AUTOSAR XML (schema 00044)
package /E40_Platform_System_SystemPackage/Components
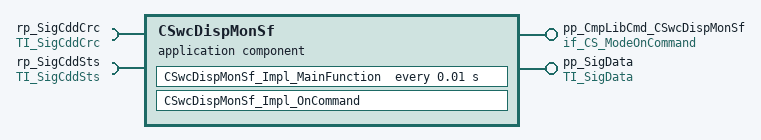
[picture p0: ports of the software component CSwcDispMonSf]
  application sw component type CSwcDispMonSf
    provide port pp_CmpLibCmd_CSwcDispMonSf: server-com-spec{operation=Impl_OnCommand, queue-length=1}, provided-interface=if_CS_ModeOnCommand
    provide port pp_SigData: nonqueued-sender-com-spec{data-element=sig0_port, init-value=constant-reference=CSwcDispMonSfsig0_portValue0}, provided-interface=TI_SigData
    require port rp_SigCddCrc: client-com-spec=Impl_sig_get_win_crc_data, required-interface=TI_SigCddCrc
    require port rp_SigCddSts: nonqueued-receiver-com-spec{data-element=win_violation_output, init-value=constant-reference=CSwcDispMonSfwin_violation_outputValue0}, required-interface=TI_SigCddSts
    behavior IB_CSwcDispMonSf
      timing event TECSwcDispMonSf_Impl_MainFunction: start-on-event=CSwcDispMonSf_Impl_MainFunction, period=0.01
      operation invoked event OIE_pp_CmpLibCmd_CSwcDispMonSf_CSwcDispMonSf_Impl_OnCommandTrigByImpl_OnCommand: start-on-event=CSwcDispMonSf_Impl_OnCommand, operation=pp_CmpLibCmd_CSwcDispMonSf.Impl_OnCommand
      port-api-options:
        enable-take-address=false, indirect-api=false, port=pp_CmpLibCmd_CSwcDispMonSf
        enable-take-address=false, indirect-api=false, port=pp_SigData
        enable-take-address=false, indirect-api=false, port=rp_SigCddCrc
        enable-take-address=false, indirect-api=false, port=rp_SigCddSts
      runnable CSwcDispMonSf_Impl_MainFunction: can-be-invoked-concurrently=true
        data-receive-point-by-arguments:
          access DRA_rp_SigCddSts_win_violation_output: accessed-variable=rp_SigCddSts.win_violation_output
        data-send-points:
          access DWA_pp_SigData_sig0_port: accessed-variable=pp_SigData.sig0_port
        sync call OA_rp_SigCddCrc_Impl_sig_get_win_crc_data: operation=rp_SigCddCrc.Impl_sig_get_win_crc_data
      runnable CSwcDispMonSf_Impl_OnCommand: can-be-invoked-concurrently=true
  swc implementation IMPL_CSwcDispMonSf: behavior=IB_CSwcDispMonSf
